AUTOSAR XML (schema 3-2-1)
package /SeatSensor
  swc implementation SeatSensorImplementation: behavior=SeatSensorBehavioral
  internal behavior SeatSensorBehavioral: component=SeatSensing
    timing event timingEventSeatSensor: start-on-event=SeatSensorMain, period=0.0
    runnable SeatSensorMain: can-be-invoked-concurrently=true, symbol=runnable_1_symbol
      data read access dataReadAccess_1: data-element=SensorIO.SensorValue
      data write access dataWriteAccess_1: data-element=SeatStatus.PassengerOnSeat
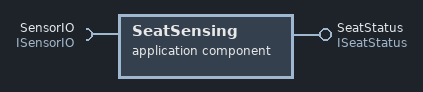
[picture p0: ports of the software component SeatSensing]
  application software component type SeatSensing
    provide port SeatStatus: provided-interface=ISeatStatus
    require port SensorIO: required-interface=ISensorIO
